# CY8C5888LTI_LP097 register map
File version: 0.1
Registers are 8-bit, read-write, no defined reset value unless marked. A register's access mark holds for its fields unless they carry their own. Offsets are from the block's base; [hi:lo] are bit positions; {n}, {i} and the like mark numbered series; 'fields as' and 'values as' point back to an identical list.

## Filter
Base 0x00000000
0x400043A6 Filter_DFB_PM_ACT_CFG_Register — Active Mode Power Control Register
  [4] en_dfb — Enable DFB(s). Populated subsystems are counted from the LSB.
    1=Enable_dfb (Enable Power to DFB); 0=Disable_dfb (Disable Power to DFB)
0x400043B6 Filter_DFB_PM_STBY_CFG_Register — Alternate Active Mode Power Control Register
  [4] en_dfb — Enable DFB(s). Populated subsystems are counted from the LSB.
    1=Enable_dfb (Enable Power to DFB during standby power mode); 0=Disable_dfb (Disable Power to DFB)
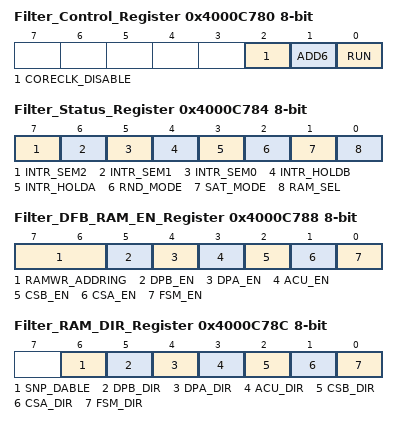
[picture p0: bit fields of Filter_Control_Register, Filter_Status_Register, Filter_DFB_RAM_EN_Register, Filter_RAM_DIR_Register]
0x4000C780 Filter_Control_Register — DFB Control Register
  [2] CORECLK_DISABLE — This bit when set high disables (gates off) the clock to the entire core of the block. This includes all FFs except those used for the AHB interface and CSRs and all 6 RAMs. When disabled (set high) the AHB interface to the CSR is still fully functional. This bit is ANDed with the primary input signal dfb_clk_en to control the clock gate. dfb_clk_en must be high and CoreCLK_Disable must be low for the clock to run.
    0=CORECLK_DISABLE_LOW (Core Clock is Enabled); 1=CORECLK_DISABLE_HIGH (Core Clock is Disabled (gated))
  [1] ADD6 — This bit is literally address bit 5 (6th bit) of the FSM RAM when addressed by the DFB Controller. It has no affect on the FSM RAM when addressed on the AHB interface. It controls the Banking feature of the FSM.
    0=ADDR6_LOW (ADDR6 is Low); 1=ADDR6_HIGH (ADDR6 is HIGH)
  [0] RUN — Setting this bit to 1 enables the DFB to run. Setting it to 0 forces the next state address of the FSM to zero of the active Bank, reinitializes the ACU's and PC's and clears the round flag, saturation flag, saturation detect flag and all 6 extended Enables in the Controller.
    0=RUN_DIS (DFB operation is halted); 1=RUN_EN (DFB is enabled to operate.)
0x4000C784 Filter_Status_Register — DFB Status Register
  [7] INTR_SEM2 — If this bit is high, semaphore register bit 2 is a source of the current interrupt. Write a '1' to this bit to clear it.
    0=SEM2_OFF (Indicates no pending Semaphore 2 Interrupt.); 1=SEM2_ON (Indicates a pending Semaphore 2 Interrupt.)
  [6] INTR_SEM1 — If this bit is high, semaphore register bit 1 is a source of the current interrupt. Write a '1' to this bit to clear it.
    0=SEM1_OFF (Indicates no pending Semaphore 1 Interrupt.); 1=SEM1_ON (Indicates a pending Semaphore 1 Interrupt.)
  [5] INTR_SEM0 — If this bit is high, semaphore register bit 0 is a source of the current interrupt. Write a '1' to this bit to clear it.
    0=SEM0_OFF (Indicates no pending Semaphore 0 Interrupt.); 1=SEM0_ON (Indicates a pending Semaphore 0 Interrupt.)
  [4] INTR_HOLDB — If this bit is high, Holding register B is a source of the current interrupt. Write a '1' to this bit to clear it. Reading the Holding register B also clears this bit.
    0=HOLDB_OFF (Indicates no pending Holding B Register Interrupt.); 1=HOLDB_ON (Indicates a pending Holding B Register Interrupt.)
  [3] INTR_HOLDA — If this bit is high, Holding register A is a source of the current interrupt. Write a '1' to this bit to clear it. Reading the Holding register A also clears this bit.
    0=HOLDA_OFF (Indicates no pending Holding A Register Interrupt.); 1=HOLDA_ON (Indicates a pending Holding A Register Interrupt.)
  [2] RND_MODE ro — Indicates that the DP is in Round mode - meaning that any result passing out of the DP unit is being rounded to a 16-bit value.
    0=RND_OFF (Indicates Round Mode is off.); 1=RND_ON (Indicates Round Mode is on.)
  [1] SAT_MODE ro — Indicates that the DP unit is in Saturation mode.
    0=SAT_OFF (Indicates Saturation mode is off.); 1=SAT_ON (Indicates Saturation mode is on.)
  [0] RAM_SEL ro — This bit indicates which Control Store memory is in use, RAM A or RAM B.
    0=RAMSEL_LOW (Control Store memory A is in use.); 1=RAMSEL_HIGH (Control Store memory B is in use.)
0x4000C788 Filter_DFB_RAM_EN_Register — DFB Ram Enable Register
  [7:6] RAMWR_ADDRING — These two bits control the write addressing of the 4 largest RAMs embedded in the DFB (CS-A, CS-B, Data-A, Data-B). The setting of these bits allows overlaid writes to occur to these memories when it is desired to fill them with like data.
    0=NO_OVERLAY (No overlay mapping.); 1=OVERLAY_CS_A_CS_B (Overlay CS A with CS B.); 2=OVERLAY_DATA_A_DATA_B (Overlay Data A with Data B.); 3=OVERLAY_CS_AB_DATA_AB (Overlay CS A/B with Data A with DATA B.)
  [5] DPB_EN — Datapath RAM B RAM enable / disable.
    0=RAM_DIS (RAM is disabled.); 1=RAM_EN (RAM is enabled.)
  [4] DPA_EN — Datapath RAM A RAM enable / disable.
    0=RAM_DIS (RAM is disabled.); 1=RAM_EN (RAM is enabled.)
  [3] ACU_EN — ACU RAM RAM enable / disable.
    0=RAM_DIS (RAM is disabled.); 1=RAM_EN (RAM is enabled.)
  [2] CSB_EN — Control Store RAM B RAM enable / disable.
    0=RAM_DIS (RAM is disabled.); 1=RAM_EN (RAM is enabled.)
  [1] CSA_EN — Control Store RAM A RAM enable / disable.
    0=RAM_DIS (RAM is disabled.); 1=RAM_EN (RAM is enabled.)
  [0] FSM_EN — FSM RAM RAM enable / disable.
    0=RAM_DIS (RAM is disabled.); 1=RAM_EN (RAM is enabled.)
0x4000C78C Filter_RAM_DIR_Register — DFB RAM Direction Register. This register controls the DFB memory direction. These bits control if each RAM of this block is embedded to the DFB function or mapped in the system address space on the AHB bus.
  [6] SNP_DABLE — The CS and DP RAMs (optionally the FSM) have address snooping logic that watches for redundant back-to-back RD cycles and disables the RAM to conserve power. Writing a 1 to this bit disables this logic for all RAMs.
    0=SNP_ENABLE (Enabled); 1=SNP_DISABLE (Disabled)
  [5] DPB_DIR — Datapath RAM B RAM Direction.
    0=RAM_DFB (DFB); 1=RAM_AHB (System Bus)
  [4] DPA_DIR — Datapath RAM A RAM Direction.
    0=RAM_DFB (DFB); 1=RAM_AHB (System Bus)
  [3] ACU_DIR — ACU RAM RAM Direction.
    0=RAM_DFB (DFB); 1=RAM_AHB (System Bus)
  [2] CSB_DIR — Control Store RAM B RAM Direction.
    0=RAM_DFB (DFB); 1=RAM_AHB (System Bus)
  [1] CSA_DIR — Control Store RAM B RAM Direction.
    0=RAM_DFB (DFB); 1=RAM_AHB (System Bus)
  [0] FSM_DIR — FSM RAM RAM Direction.
    0=RAM_DFB (DFB); 1=RAM_AHB (System Bus)
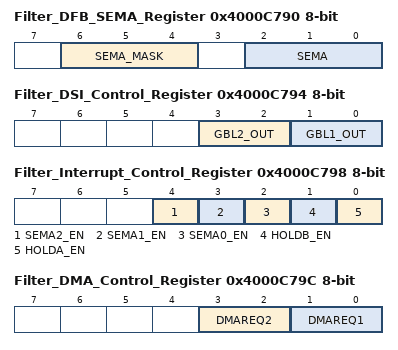
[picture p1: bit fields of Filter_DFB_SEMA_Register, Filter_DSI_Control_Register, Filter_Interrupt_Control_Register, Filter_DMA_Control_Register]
0x4000C790 Filter_DFB_SEMA_Register — DFB Semaphore Register
  [6:4] SEMA_MASK wo — These bits are used to mask writes to bits 2-0. They are write-only. If bit 4 is a 1 then the value on bit 0 will be written to SEM0, otherwise SEM0 will not be altered. Likewise for MASK1 and SEM1, and MASK2 and SEM2.
  [2:0] SEMA — These bits are used to pass semaphores between the DFB Controller and the System SW. Their definition is user defined. There is no HW implementing an arbitration methodology should both the System and Control access the same SEM bit at the same time.
0x4000C794 Filter_DSI_Control_Register — DFB Global Cotrol Register
  [3:2] GBL2_OUT — These bits are used to control what internal signals are mapped to the primary output signal dfb_globalo2.
    0=SEM2 (Semaphore Bit 2. This is the same signal described in the DFB0_SEMA CSR.); 1=DPSIGN (Datapath Sign. This signal asserts anytime the output of the ALU in the Datapath unit is negative. It will remain high for each cycle this condition is true.); 2=DPTHREASH (Datapath Threashold Crossed. This signal asserts anytime the threashold of 0 is crossed in the ALU when one of the following instructions is executing: TDECA, TSUBA, TSUBB, TADDABSA, TADDABSB. It will remain high for each cycle this condition is true.); 3=DPEQ (Datapath ALU=0. This signal asserts high when the output of the ALU in the Datapath unit equals 0 and one of the following ALU commands is executing: TDECA, TSUBA, TSUBB, TADDABSA, TADDABSB. It will remain high for each cycle this condition is true.)
  [1:0] GBL1_OUT — These bits are used to control what internal signals are mapped to the primary output signal dfb_globalo1.
    0=DFB_RUN (DFB RUN Bit. This is the same bit as the RUN bit in the DFB0_CR register.); 1=SEM0 (Semaphore Bit 0. This is the same signal described in the DFB0_SEMA CSR.); 2=SEM1 (Semaphore Bit 1. This is the same signal described in the DFB0_SEMA CSR.); 3=DFB_INTR (DFB Interrupt. This is the same signal as the primary dfb_intr output signal.)
0x4000C798 Filter_Interrupt_Control_Register — DFB Interrupt Control Register
  [4] SEMA2_EN — If this bit is set high, an interrupt is generated each time a 1 is written into the semaphore register bit 2.
    0=ENABLE_SEMAPHORE_2_IRQ_DIS (Semaphore register interrupt masked.); 1=ENABLE_SEMAPHORE_2_IRQ_EN (Interrupt is generated each time a 1 is written to the semaphore register.)
  [3] SEMA1_EN — If this bit is set high, an interrupt is generated each time a 1 is written into the semaphore register bit 1.
    0=ENABLE_SEMAPHORE_1_IRQ_DIS (Semaphore register interrupt masked.); 1=ENABLE_SEMAPHORE_1_IRQ_EN (Interrupt is generated each time a 1 is written to the semaphore register.)
  [2] SEMA0_EN — If this bit is set high, an interrupt is generated each time a 1 is written into the semaphore register bit 0.
    0=ENABLE_SEMAPHORE_0_IRQ_DIS (Semaphore register interrupt masked.); 1=ENABLE_SEMAPHORE_0_IRQ_EN (Interrupt is generated each time a 1 is written to the semaphore register.)
  [1] HOLDB_EN — If this bit is set high, an interrupt is generated each time new valid data is written into the output Holding register B.
    0=ENABLE_HOLDING_B_IRQ_DIS (Holding register interrupt masked.); 1=ENABLE_HOLDING_B_IRQ_EN (Interrupt is generated each time new valid data is written inot the output Holding B register.)
  [0] HOLDA_EN — If this bit is set high, an interrupt is generated each time new valid data is written into the output Holding register A.
    0=ENABLE_HOLDING_A_IRQ_DIS (Holding register interrupt masked.); 1=ENABLE_HOLDING_A_IRQ_EN (Interrupt is generated each time new valid data is written inot the output Holding A register.)
0x4000C79C Filter_DMA_Control_Register — DFB DMAREQ Control Register
  [3:2] DMAREQ2 — The value in these two bits selects which event drives dma_req2.
    0=DMAREQ2_DISABLED (Disabled); 1=DMAREQ2_HOLDING_REG_B (New data in Holding Register B.); 2=DMAREQ2_SEMAPHORE_0 (Semaphore 0.); 3=DMAREQ2_SEMAPHORE_1 (Semaphore 1.)
  [1:0] DMAREQ1 — The value in these two bits selects which event drives dma_req1.
    0=DMAREQ1_DISABLED (Disabled); 1=DMAREQ1_HOLDING_REG_A (New data in Holding Register A.); 2=DMAREQ1_SEMAPHORE_0 (Semaphore 0.); 3=DMAREQ1_SEMAPHORE_1 (Semaphore 1.)
0x4000C7A0 Filter_STAGEA_Register — DFB_STAGEA (Input Low Byte) Register
  [7:0] STGA_LOW — This is the low byte of the Streaming input Staging Register - Port A.
0x4000C7A1 Filter_STAGEAM_Register — DFB_STAGEAM (Input Middle Byte) Register
  [7:0] STGA_MID — This is the middle byte of the Streaming input Staging Register - Port A.
0x4000C7A2 Filter_STAGEAH_Register — DFB_STAGEAH (Input High Byte) Register
  [7:0] STGA_HIGH — This is the high byte of the Streaming input Staging Register - Port A.
0x4000C7A4 Filter_STAGEB_Register — DFB_STAGEB (Input Low Byte) Register
  [7:0] STGB_LOW — This is the low byte of the Streaming input Staging Register - Port B.
0x4000C7A5 Filter_STAGEBM_Register — DFB_STAGEBM (Input Middle Byte) Register
  [7:0] STGB_MID — This is the middle byte of the Streaming input Staging Register - Port B.
0x4000C7A6 Filter_STAGEBH_Register — DFB_STAGEBH (Input High Byte) Register
  [7:0] STGB_HIGH — This is the high byte of the Streaming input Staging Register - Port B.
0x4000C7A8 Filter_HOLDA_Register — DFB_HOLDA (Output Low Byte) Register
  [7:0] HOLDA_LOW ro — This is the low byte of the output Holding Register - Port A.
0x4000C7A9 Filter_HOLDAM_Register — DFB_HOLDAM (Output Middle Byte) Register
  [7:0] HOLDA_MID ro — This is the middle byte of the output Holding Register - Port A.
0x4000C7AA Filter_HOLDAH_Register — DFB_HOLDAH (Output High Byte) Register
  [7:0] HOLDA_HIGH ro — This is the high byte of the output Holding Register - Port A.
0x4000C7AC Filter_HOLDB_Register — DFB_HOLDB (Output Low Byte) Register
  [7:0] HOLDB_LOW ro — This is the low byte of the output Holding Register - Port B.
0x4000C7AD Filter_HOLDBM_Register — DFB_HOLDBM (Output Middle Byte) Register
  [7:0] HOLDB_MID ro — This is the middle byte of the output Holding Register - Port B.
0x4000C7AE Filter_HOLDBH_Register — DFB_HOLDBH (Output High Byte) Register
  [7:0] HOLDB_HIGH ro — This is the high byte of the output Holding Register - Port B.
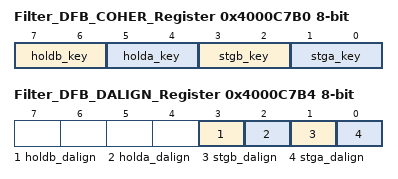
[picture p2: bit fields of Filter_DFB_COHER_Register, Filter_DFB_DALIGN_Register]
0x4000C7B0 Filter_DFB_COHER_Register — DFB Coherency Register
  [7:6] holdb_key — Sets the Key Coherency Byte of the Holding B register
    0=HOLDB_KEY_LOW (Key Byte is low byte.); 1=HOLDB_KEY_MID (Key Byte is middle byte.); 2=HOLDB_KEY_HIGH (Key Byte is high byte.)
  [5:4] holda_key — Sets the Key Coherency Byte of the Holding A register
    0=HOLDA_KEY_LOW (Key Byte is low byte.); 1=HOLDA_KEY_MID (Key Byte is middle byte.); 2=HOLDA_KEY_HIGH (Key Byte is high byte.)
  [3:2] stgb_key — Sets the Key Coherency Byte of the Staging B register.
    0=STGB_KEY_LOW (Key Byte is low byte.); 1=STGB_KEY_MID (Key Byte is middle byte.); 2=STGB_KEY_HIGH (Key Byte is high byte.)
  [1:0] stga_key — Sets the Key Coherency Byte of the Staging A register.
    0=STGA_KEY_LOW (Key Byte is low byte.); 1=STGA_KEY_MID (Key Byte is middle byte.); 2=STGA_KEY_HIGH (Key Byte is high byte.)
0x4000C7B4 Filter_DFB_DALIGN_Register — DFB Data Align Register
  [3] holdb_dalign — Shifts the read right by a byte.
    0=HOLDB_DALIGN_LOW (Reads normally.); 1=HOLDB_DALIGN_HIGH (Reads shifted right by 8-bits.)
  [2] holda_dalign — Shifts the read right by a byte.
    0=HOLDA_DALIGN_LOW (Reads normally.); 1=HOLDA_DALIGN_HIGH (Reads shifted right by 8-bits.)
  [1] stgb_dalign — Shifts the write left by a byte.
    0=STGB_DALIGN_LOW (Writes normally.); 1=STGB_DALIGN_HIGH (Writes shifted left by 8-bits.)
  [0] stga_dalign — Shifts the write left by a byte.
    0=STGA_DALIGN_LOW (Writes normally.); 1=STGA_DALIGN_HIGH (Writes shifted left by 8-bits.)

## Opamp
Base 0x00000000
0x400043A4 PM_ACT_CFG4 — Active Power Mode Configuration Register 4
  [3:0] EN_OPAMP — Enables subsystems during active power mode
    0=Blk_0 (Enables analog linear output buffer for Opamp block 0); 2=Blk_1 (Enables analog linear output buffer for Opamp block 1); 4=Blk_2 (Enables analog linear output buffer for Opamp block 2); 8=Blk_3 (Enables analog linear output buffer for Opamp block 3)
0x400043B4 PM_STBY_CFG4 — Standby Power Mode Configuration Register 4
  [3:0] EN_OPAMP — Enables subsystems during standby power mode
    values as PM_ACT_CFG4.EN_OPAMP
0x40004624 OPAMP__TR0 — Analog Output Buffer Trim Register 0
  [4:0] offset_trim — Offset Trim: 420uV typical step size; +/- 6.8mV offset trimmable range
0x40004625 OPAMP__TR1 — Analog Output Buffer Trim Register 1
0x4000585C OPAMP__CR — Analog Output Buffer Configuration Register
  [1:0] pwr_mode — Power Mode
    0=Default_Fast (Default Power mode Fast); 1=Slow (Power Mode Slow); 2=Medium (Power Mode Medium); 3=Fast (Power Mode Fast)
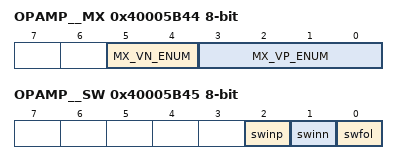
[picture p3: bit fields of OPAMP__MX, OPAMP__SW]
0x40005B44 OPAMP__MX — Analog Buffer Input Selection Register
  [5:4] MX_VN_ENUM — MUX select VN (Negative terminal input)
    0=OPAMP0_MX_VN_DEFAULT (Default - Not Connected (NC)); 1=OPAMP0_MX_VN_AG4 (MUX Selection AGL(4)); 2=OPAMP0_MX_VN_AG6 (MUX Selection AGL(6)); 3=OPAMP0_MX_VN_0x3 (Reserved (NC))
  [3:0] MX_VP_ENUM — MUX select VP (Positive terminal input)
    0=OPAMP0_MX_VP_DEFAULT (Default - Not Connected (NC)); {v}=OPAMP0_MX_VP_AG{v+3} (MUX Selection AGL({v+3})) (v=1..4); {v}=OPAMP0_MX_VP_ABUS{v-5} (MUX Selection ABUSL({v-5})) (v=5..8); 9=OPAMP0_MX_VP_VREF (MUX Selection: OPAMP Voltage Reference); {v}=OPAMP0_MX_VP_H_{0x0+v} (Reserved (NC)) (v=10..15)
0x40005B45 OPAMP__SW — Analog Buffer Routing Switch Register
  [2] swinp — Switch Enable Positive Input
  [1] swinn — Switch Enable Negative Input
  [0] swfol — Switch Enable Follow
